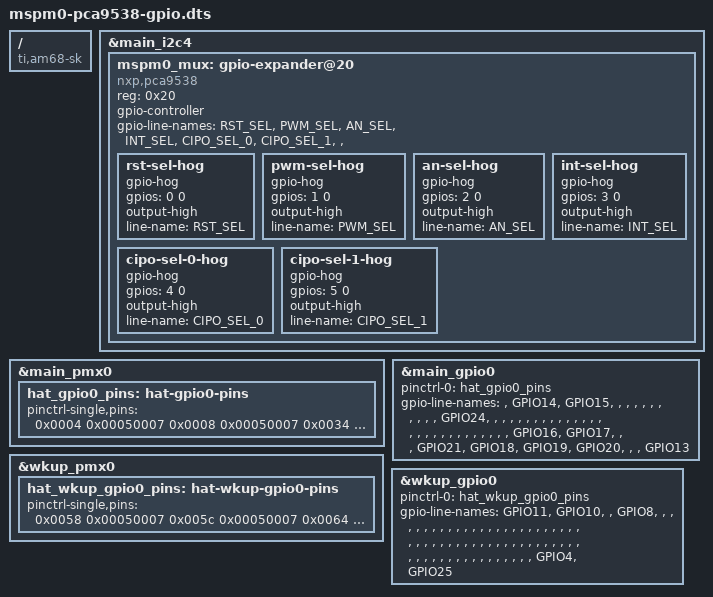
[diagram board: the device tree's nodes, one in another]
/dts-v1/;
/plugin/;

/ {
	compatible = "ti,am68-sk", "ti,j721s2";

	fragment@0 {
		/* SK-AM68 40-pin expansion header pins 3/5 are I2C4. */
		target = <&main_i2c4>;
		__overlay__ {
			#address-cells = <1>;
			#size-cells = <0>;

			mspm0_mux: gpio-expander@20 {
				compatible = "nxp,pca9538";
				reg = <0x20>;
				gpio-controller;
				#gpio-cells = <2>;
				gpio-line-names =
					"RST_SEL",
					"PWM_SEL",
					"AN_SEL",
					"INT_SEL",
					"CIPO_SEL_0",
					"CIPO_SEL_1",
					"",
					"";
				status = "okay";

				/* TI AM68 SK-EVM audio-board routing defaults. */
				rst-sel-hog {
					gpio-hog;
					gpios = <0 0>;
					output-high;
					line-name = "RST_SEL";
				};

				pwm-sel-hog {
					gpio-hog;
					gpios = <1 0>;
					output-high;
					line-name = "PWM_SEL";
				};

				an-sel-hog {
					gpio-hog;
					gpios = <2 0>;
					output-high;
					line-name = "AN_SEL";
				};

				int-sel-hog {
					gpio-hog;
					gpios = <3 0>;
					output-high;
					line-name = "INT_SEL";
				};

				cipo-sel-0-hog {
					gpio-hog;
					gpios = <4 0>;
					output-high;
					line-name = "CIPO_SEL_0";
				};

				cipo-sel-1-hog {
					gpio-hog;
					gpios = <5 0>;
					output-high;
					line-name = "CIPO_SEL_1";
				};
			};
		};
	};

	fragment@1 {
		target = <&main_pmx0>;
		__overlay__ {
			hat_gpio0_pins: hat-gpio0-pins {
				pinctrl-single,pins = <
					0x0004 0x00050007 /* HAT pin 8 / GPIO14 / W25 / GPIO0_1 input */
					0x0008 0x00050007 /* HAT pin 10 / GPIO15 / AC24 / GPIO0_2 input */
					0x0034 0x00050007 /* HAT pin 18 / GPIO24 / AD24 / GPIO0_13 input */
					0x00a8 0x00050007 /* HAT pin 11 / GPIO17 / U24 / GPIO0_42 input */
					0x00b4 0x00050007 /* HAT pin 40 / GPIO21 / U25 / GPIO0_45 input */
					0x00b8 0x00050007 /* HAT pin 12 / GPIO18 / AA24 / GPIO0_46 input */
					0x00bc 0x00050007 /* HAT pin 35 / GPIO19 / V28 / GPIO0_47 input */
					0x00c0 0x00050007 /* HAT pin 38 / GPIO20 / T28 / GPIO0_48 input */
					0x00cc 0x00050007 /* HAT pin 33 / GPIO13 / AE27 / GPIO0_51 input */
				>;
			};
		};
	};

	fragment@2 {
		target = <&wkup_pmx0>;
		__overlay__ {
			hat_wkup_gpio0_pins: hat-wkup-gpio0-pins {
				pinctrl-single,pins = <
					0x0058 0x00050007 /* HAT pin 23 / GPIO11 / D26 / WKUP_GPIO0_0 input */
					0x005c 0x00050007 /* HAT pin 19 / GPIO10 / E24 / WKUP_GPIO0_1 input */
					0x0064 0x00050007 /* HAT pin 24 / GPIO8 / C27 / WKUP_GPIO0_3 input */
					0x011c 0x00040007 /* HAT pin 22 / GPIO25 / J27 / WKUP_GPIO0_67 input, pull-down */
					0x0180 0x00050007 /* HAT pin 7 / GPIO4 / G25 / WKUP_GPIO0_66 input */
				>;
			};
		};
	};

	fragment@3 {
		target = <&main_gpio0>;
		__overlay__ {
			pinctrl-names = "default";
			pinctrl-0 = <&hat_gpio0_pins>;
			gpio-line-names = "", "GPIO14", "GPIO15", "", "", "", "", "", "", "",
				"", "", "", "GPIO24", "", "", "", "", "", "",
				"", "", "", "", "", "", "", "", "", "",
				"", "", "", "", "", "", "", "", "", "",
				"", "GPIO16", "GPIO17", "", "", "GPIO21", "GPIO18",
				"GPIO19", "GPIO20", "", "", "GPIO13";
			status = "okay";
		};
	};

	fragment@4 {
		target = <&wkup_gpio0>;
		__overlay__ {
			pinctrl-names = "default";
			pinctrl-0 = <&hat_wkup_gpio0_pins>;
			gpio-line-names = "GPIO11", "GPIO10", "", "GPIO8", "", "", "", "", "", "",
				"", "", "", "", "", "", "", "", "", "",
				"", "", "", "", "", "", "", "", "", "",
				"", "", "", "", "", "", "", "", "", "",
				"", "", "", "", "", "", "", "", "", "",
				"", "", "", "", "", "", "", "", "", "",
				"", "", "", "", "", "", "GPIO4", "GPIO25";
			status = "okay";
		};
	};
};
